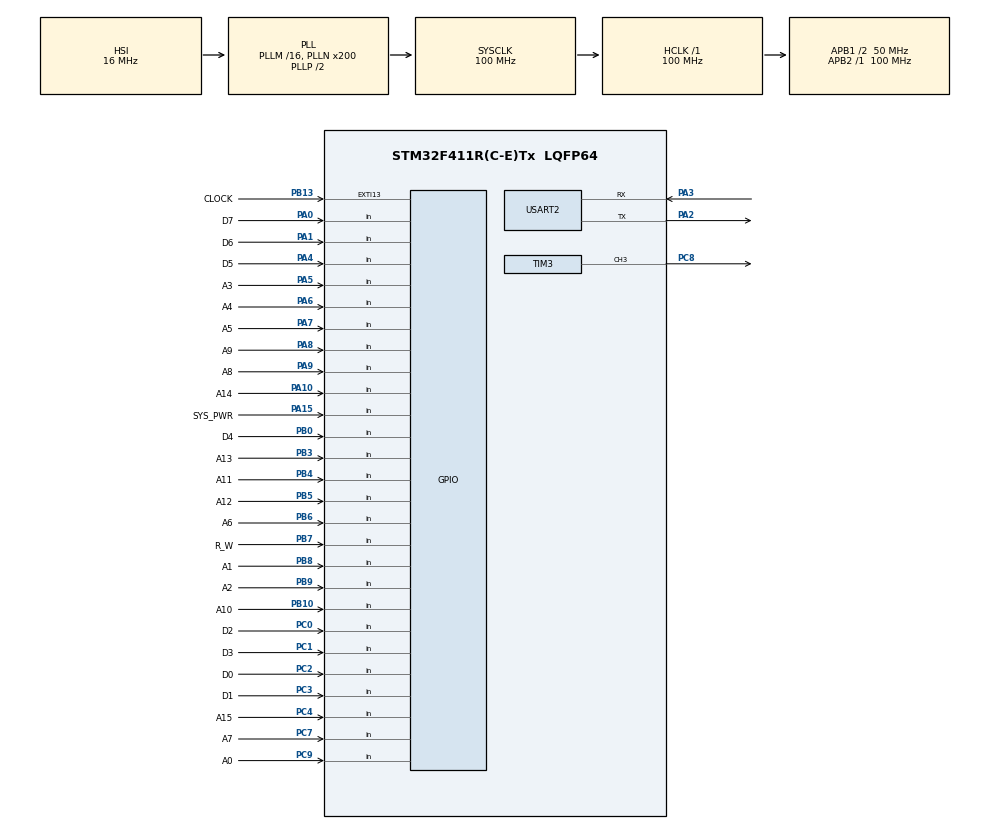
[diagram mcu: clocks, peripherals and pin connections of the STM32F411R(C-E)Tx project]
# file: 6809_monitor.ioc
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Mcu.Family=STM32F4
Mcu.Name=STM32F411R(C-E)Tx
Mcu.Package=LQFP64
NVIC.EXTI15_10_IRQn=true\:0\:0\:false\:false\:true\:true\:true\:true
NVIC.PriorityGroup=NVIC_PRIORITYGROUP_4
PA0-WKUP.GPIO_Label=D7
PA0-WKUP.GPIO_PuPd=GPIO_PULLDOWN
PA0-WKUP.Signal=GPIO_Input
PA1.GPIO_Label=D6
PA1.GPIO_PuPd=GPIO_PULLDOWN
PA1.Signal=GPIO_Input
PA10.GPIO_Label=A14
PA10.GPIO_PuPd=GPIO_PULLDOWN
PA10.Signal=GPIO_Input
PA15.GPIO_Label=SYS_PWR
PA15.GPIO_PuPd=GPIO_PULLDOWN
PA15.Signal=GPIO_Input
PA2.Mode=Asynchronous
PA2.Signal=USART2_TX
PA3.Mode=Asynchronous
PA3.Signal=USART2_RX
PA4.GPIO_Label=D5
PA4.GPIO_PuPd=GPIO_PULLDOWN
PA4.Signal=GPIO_Input
PA5.GPIO_Label=A3
PA5.GPIO_PuPd=GPIO_PULLDOWN
PA5.Signal=GPIO_Input
PA6.GPIO_Label=A4
PA6.GPIO_PuPd=GPIO_PULLDOWN
PA6.Signal=GPIO_Input
PA7.GPIO_Label=A5
PA7.GPIO_PuPd=GPIO_PULLDOWN
PA7.Signal=GPIO_Input
PA8.GPIO_Label=A9
PA8.GPIO_PuPd=GPIO_PULLDOWN
PA8.Signal=GPIO_Input
PA9.GPIO_Label=A8
PA9.GPIO_PuPd=GPIO_PULLDOWN
PA9.Signal=GPIO_Input
PB0.GPIO_Label=D4
PB0.GPIO_PuPd=GPIO_PULLDOWN
PB0.Signal=GPIO_Input
PB10.GPIO_Label=A10
PB10.GPIO_PuPd=GPIO_PULLDOWN
PB10.Signal=GPIO_Input
PB13.GPIO_Label=CLOCK
PB13.GPIO_PuPd=GPIO_PULLDOWN
PB13.Signal=GPXTI13
PB3.GPIO_Label=A13
PB3.GPIO_PuPd=GPIO_PULLDOWN
PB3.Signal=GPIO_Input
PB4.GPIO_Label=A11
PB4.GPIO_PuPd=GPIO_PULLDOWN
PB4.Signal=GPIO_Input
PB5.GPIO_Label=A12
PB5.GPIO_PuPd=GPIO_PULLDOWN
PB5.Signal=GPIO_Input
PB6.GPIO_Label=A6
PB6.GPIO_PuPd=GPIO_PULLDOWN
PB6.Signal=GPIO_Input
PB7.GPIO_Label=R_W
PB7.GPIO_PuPd=GPIO_PULLDOWN
PB7.Signal=GPIO_Input
PB8.GPIO_Label=A1
PB8.GPIO_PuPd=GPIO_PULLDOWN
PB8.Signal=GPIO_Input
PB9.GPIO_Label=A2
PB9.GPIO_PuPd=GPIO_PULLDOWN
PB9.Signal=GPIO_Input
PC0.GPIO_Label=D2
PC0.GPIO_PuPd=GPIO_PULLDOWN
PC0.Signal=GPIO_Input
PC1.GPIO_Label=D3
PC1.GPIO_PuPd=GPIO_PULLDOWN
PC1.Signal=GPIO_Input
PC2.GPIO_Label=D0
PC2.GPIO_PuPd=GPIO_PULLDOWN
PC2.Signal=GPIO_Input
PC3.GPIO_Label=D1
PC3.GPIO_PuPd=GPIO_PULLDOWN
PC3.Signal=GPIO_Input
PC4.GPIO_Label=A15
PC4.GPIO_PuPd=GPIO_PULLDOWN
PC4.Signal=GPIO_Input
PC7.GPIO_Label=A7
PC7.GPIO_PuPd=GPIO_PULLDOWN
PC7.Signal=GPIO_Input
PC8.Signal=S_TIM3_CH3
PC9.GPIO_Label=A0
PC9.GPIO_PuPd=GPIO_PULLDOWN
PC9.Signal=GPIO_Input
ProjectManager.HeapSize=0x200
ProjectManager.StackSize=0x400
ProjectManager.TargetToolchain=CMake
RCC.48MHZClocksFreq_Value=50000000
RCC.AHBFreq_Value=100000000
RCC.APB1CLKDivider=RCC_HCLK_DIV2
RCC.APB1Freq_Value=50000000
RCC.APB1TimFreq_Value=100000000
RCC.APB2Freq_Value=100000000
RCC.APB2TimFreq_Value=100000000
RCC.CortexFreq_Value=100000000
RCC.HCLKFreq_Value=100000000
RCC.HSE_VALUE=25000000
RCC.HSI_VALUE=16000000
RCC.LSE_VALUE=32768
RCC.PLLN=200
RCC.SYSCLKFreq_VALUE=100000000
RCC.SYSCLKSource=RCC_SYSCLKSOURCE_PLLCLK
RCC.VCOOutputFreq_Value=200000000
SH.S_TIM3_CH3.0=TIM3_CH3,PWM Generation3 CH3
TIM3.AutoReloadPreload=TIM_AUTORELOAD_PRELOAD_ENABLE
TIM3.Channel-PWM\ Generation3\ CH3=TIM_CHANNEL_3
TIM3.ClockDivision=TIM_CLOCKDIVISION_DIV4
TIM3.Period=999
TIM3.Prescaler=25
TIM3.Pulse-PWM\ Generation3\ CH3=500
USART2.VirtualMode=VM_ASYNC
VP_TIM3_VS_ClockSourceINT.Mode=Internal
board=custom

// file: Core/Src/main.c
/* USER CODE BEGIN Header */
/**
  ******************************************************************************
  * @file           : main.c
  * @brief          : Main program body
  ******************************************************************************
  * @attention
  *
  * Copyright (c) 2025 STMicroelectronics.
  * All rights reserved.
  *
  * This software is licensed under terms that can be found in the LICENSE file
  * in the root directory of this software component.
  * If no LICENSE file comes with this software, it is provided AS-IS.
  *
  ******************************************************************************
  */
/* USER CODE END Header */
#include "main.h"

/* USER CODE BEGIN Includes */
#include <string.h>
/* USER CODE END Includes */

TIM_HandleTypeDef htim3;

UART_HandleTypeDef huart2;

void SystemClock_Config(void);
static void MX_GPIO_Init(void);
static void MX_TIM3_Init(void);
static void MX_USART2_UART_Init(void);

int main(void)
{

  /* MCU Configuration--------------------------------------------------------*/

  /* Reset of all peripherals, Initializes the Flash interface and the Systick. */
  HAL_Init();

  /* Configure the system clock */
  SystemClock_Config();

  /* Initialize all configured peripherals */
  MX_GPIO_Init();
  MX_TIM3_Init();
  MX_USART2_UART_Init();
  /* USER CODE BEGIN 2 */
  /* Start PWM on TIM3 Channel 3 (PC8) */
  HAL_TIM_PWM_Start(&htim3, TIM_CHANNEL_3);
  /* USER CODE END 2 */

  /* Infinite loop */
  while (1)
  {

  }
}

void SystemClock_Config(void)
{
  RCC_OscInitTypeDef RCC_OscInitStruct = {0};
  RCC_ClkInitTypeDef RCC_ClkInitStruct = {0};

  /** Configure the main internal regulator output voltage
  */
  __HAL_RCC_PWR_CLK_ENABLE();
  __HAL_PWR_VOLTAGESCALING_CONFIG(PWR_REGULATOR_VOLTAGE_SCALE1);

  /** Initializes the RCC Oscillators according to the specified parameters
  * in the RCC_OscInitTypeDef structure.
  */
  RCC_OscInitStruct.OscillatorType = RCC_OSCILLATORTYPE_HSI;
  RCC_OscInitStruct.HSIState = RCC_HSI_ON;
  RCC_OscInitStruct.HSICalibrationValue = RCC_HSICALIBRATION_DEFAULT;
  RCC_OscInitStruct.PLL.PLLState = RCC_PLL_ON;
  RCC_OscInitStruct.PLL.PLLSource = RCC_PLLSOURCE_HSI;
  RCC_OscInitStruct.PLL.PLLM = 16;
  RCC_OscInitStruct.PLL.PLLN = 200;
  RCC_OscInitStruct.PLL.PLLP = RCC_PLLP_DIV2;
  RCC_OscInitStruct.PLL.PLLQ = 4;
  if (HAL_RCC_OscConfig(&RCC_OscInitStruct) != HAL_OK)
  {
    Error_Handler();
  }

  /** Initializes the CPU, AHB and APB buses clocks
  */
  RCC_ClkInitStruct.ClockType = RCC_CLOCKTYPE_HCLK|RCC_CLOCKTYPE_SYSCLK
                              |RCC_CLOCKTYPE_PCLK1|RCC_CLOCKTYPE_PCLK2;
  RCC_ClkInitStruct.SYSCLKSource = RCC_SYSCLKSOURCE_PLLCLK;
  RCC_ClkInitStruct.AHBCLKDivider = RCC_SYSCLK_DIV1;
  RCC_ClkInitStruct.APB1CLKDivider = RCC_HCLK_DIV2;
  RCC_ClkInitStruct.APB2CLKDivider = RCC_HCLK_DIV1;

  if (HAL_RCC_ClockConfig(&RCC_ClkInitStruct, FLASH_LATENCY_3) != HAL_OK)
  {
    Error_Handler();
  }
}

static void MX_TIM3_Init(void)
{

  TIM_ClockConfigTypeDef sClockSourceConfig = {0};
  TIM_MasterConfigTypeDef sMasterConfig = {0};
  TIM_OC_InitTypeDef sConfigOC = {0};

  htim3.Instance = TIM3;
  htim3.Init.Prescaler = 25;
  htim3.Init.CounterMode = TIM_COUNTERMODE_UP;
  htim3.Init.Period = 999;
  htim3.Init.ClockDivision = TIM_CLOCKDIVISION_DIV4;
  htim3.Init.AutoReloadPreload = TIM_AUTORELOAD_PRELOAD_ENABLE;
  if (HAL_TIM_Base_Init(&htim3) != HAL_OK)
  {
    Error_Handler();
  }
  sClockSourceConfig.ClockSource = TIM_CLOCKSOURCE_INTERNAL;
  if (HAL_TIM_ConfigClockSource(&htim3, &sClockSourceConfig) != HAL_OK)
  {
    Error_Handler();
  }
  if (HAL_TIM_PWM_Init(&htim3) != HAL_OK)
  {
    Error_Handler();
  }
  sMasterConfig.MasterOutputTrigger = TIM_TRGO_RESET;
  sMasterConfig.MasterSlaveMode = TIM_MASTERSLAVEMODE_DISABLE;
  if (HAL_TIMEx_MasterConfigSynchronization(&htim3, &sMasterConfig) != HAL_OK)
  {
    Error_Handler();
  }
  sConfigOC.OCMode = TIM_OCMODE_PWM1;
  sConfigOC.Pulse = 500;
  sConfigOC.OCPolarity = TIM_OCPOLARITY_HIGH;
  sConfigOC.OCFastMode = TIM_OCFAST_DISABLE;
  if (HAL_TIM_PWM_ConfigChannel(&htim3, &sConfigOC, TIM_CHANNEL_3) != HAL_OK)
  {
    Error_Handler();
  }
  HAL_TIM_MspPostInit(&htim3);

}

static void MX_USART2_UART_Init(void)
{

  huart2.Instance = USART2;
  huart2.Init.BaudRate = 115200;
  huart2.Init.WordLength = UART_WORDLENGTH_8B;
  huart2.Init.StopBits = UART_STOPBITS_1;
  huart2.Init.Parity = UART_PARITY_NONE;
  huart2.Init.Mode = UART_MODE_TX_RX;
  huart2.Init.HwFlowCtl = UART_HWCONTROL_NONE;
  huart2.Init.OverSampling = UART_OVERSAMPLING_16;
  if (HAL_UART_Init(&huart2) != HAL_OK)
  {
    Error_Handler();
  }

}

static void MX_GPIO_Init(void)
{
  GPIO_InitTypeDef GPIO_InitStruct = {0};

  /* GPIO Ports Clock Enable */
  __HAL_RCC_GPIOC_CLK_ENABLE();
  __HAL_RCC_GPIOA_CLK_ENABLE();
  __HAL_RCC_GPIOB_CLK_ENABLE();

  /*Configure GPIO pins : D2_Pin D3_Pin D0_Pin D1_Pin
                           A15_Pin A7_Pin A0_Pin */
  GPIO_InitStruct.Pin = D2_Pin|D3_Pin|D0_Pin|D1_Pin
                          |A15_Pin|A7_Pin|A0_Pin;
  GPIO_InitStruct.Mode = GPIO_MODE_INPUT;
  GPIO_InitStruct.Pull = GPIO_NOPULL;  /* No pull for passive monitoring */
  HAL_GPIO_Init(GPIOC, &GPIO_InitStruct);

  /*Configure GPIO pins : D7_Pin D6_Pin D5_Pin A3_Pin
                           A4_Pin A5_Pin A9_Pin A8_Pin
                           A14_Pin */
  GPIO_InitStruct.Pin = D7_Pin|D6_Pin|D5_Pin|A3_Pin
                          |A4_Pin|A5_Pin|A9_Pin|A8_Pin
                          |A14_Pin;
  GPIO_InitStruct.Mode = GPIO_MODE_INPUT;
  GPIO_InitStruct.Pull = GPIO_NOPULL;  /* No pull for passive monitoring */
  HAL_GPIO_Init(GPIOA, &GPIO_InitStruct);

  /*Configure GPIO pin : SYS_PWR_Pin */
  GPIO_InitStruct.Pin = SYS_PWR_Pin;
  GPIO_InitStruct.Mode = GPIO_MODE_INPUT;
  GPIO_InitStruct.Pull = GPIO_PULLDOWN;  /* Keep pull-down for power detection */
  HAL_GPIO_Init(GPIOA, &GPIO_InitStruct);

  /*Configure GPIO pins : D4_Pin A10_Pin A13_Pin A11_Pin
                           A12_Pin A6_Pin R_W_Pin A1_Pin
                           A2_Pin */
  GPIO_InitStruct.Pin = D4_Pin|A10_Pin|A13_Pin|A11_Pin
                          |A12_Pin|A6_Pin|R_W_Pin|A1_Pin
                          |A2_Pin;
  GPIO_InitStruct.Mode = GPIO_MODE_INPUT;
  GPIO_InitStruct.Pull = GPIO_NOPULL;  /* No pull for passive monitoring */
  HAL_GPIO_Init(GPIOB, &GPIO_InitStruct);

  /*Configure GPIO pin : CLOCK_Pin */
  GPIO_InitStruct.Pin = CLOCK_Pin;
  GPIO_InitStruct.Mode = GPIO_MODE_IT_RISING;
  GPIO_InitStruct.Pull = GPIO_NOPULL;  /* No pull for passive monitoring */
  HAL_GPIO_Init(CLOCK_GPIO_Port, &GPIO_InitStruct);

  /* EXTI interrupt init*/
  HAL_NVIC_SetPriority(EXTI15_10_IRQn, 0, 0);
  HAL_NVIC_EnableIRQ(EXTI15_10_IRQn);

}

void Error_Handler(void)
{
  __disable_irq();
  while (1)
  {
  }
}
